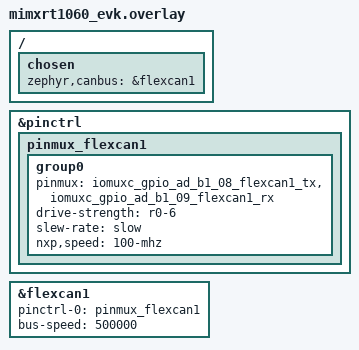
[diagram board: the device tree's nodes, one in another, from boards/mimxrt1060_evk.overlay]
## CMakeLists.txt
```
cmake_minimum_required(VERSION 3.20.0)

find_package(Zephyr REQUIRED HINTS $ENV{ZEPHYR_BASE})

project(zephyr_can_monitor VERSION 1.0.0)

target_sources(app PRIVATE
    src/main.c
    src/can_monitor.c
    src/can_tx.c
    src/logger.c
)

target_include_directories(app PRIVATE src)
```

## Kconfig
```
mainmenu "CAN Monitor"

source "Kconfig.zephyr"

rsource "Kconfig.appsymbols"
```

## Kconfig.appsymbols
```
# App-specific Kconfig symbols shared between the application and unit tests.
# Sourced from the root Kconfig and from each test's Kconfig.

menu "CAN Logger Configuration"

config CAN_LOGGER_BITRATE
	int "CAN bus bitrate (bps)"
	default 500000
	help
	  CAN bus bitrate in bits per second.
	  Common values: 125000, 250000, 500000, 1000000.

config CAN_TX1_PERIOD_MS
	int "TX message 1 period (ms)"
	default 100
	range 10 60000
	help
	  Transmit interval for TX message 1 in milliseconds.

config CAN_TX2_PERIOD_MS
	int "TX message 2 period (ms)"
	default 500
	range 10 60000
	help
	  Transmit interval for TX message 2 in milliseconds.

config CAN_TX3_PERIOD_MS
	int "TX message 3 period (ms)"
	default 1000
	range 10 60000
	help
	  Transmit interval for TX message 3 in milliseconds.

config CAN_TX1_ID
	hex "TX message 1 CAN ID (11-bit)"
	default 0x101
	range 0x001 0x7FF
	help
	  11-bit CAN ID used for the first periodic TX message.

config CAN_TX2_ID
	hex "TX message 2 CAN ID (11-bit)"
	default 0x102
	range 0x001 0x7FF
	help
	  11-bit CAN ID used for the second periodic TX message.

config CAN_TX3_ID
	hex "TX message 3 CAN ID (11-bit)"
	default 0x103
	range 0x001 0x7FF
	help
	  11-bit CAN ID used for the third periodic TX message.

config CAN_ID_START_ENABLED
	bool "Enable start logging RX ID"
	default n
	help
	  When enabled, logging does not begin until a CAN frame with
	  CAN_ID_START is received. When disabled, logging starts immediately.

config CAN_ID_START
	hex "RX CAN ID to start logging"
	depends on CAN_ID_START_ENABLED
	default 0x200
	range 0x001 0x7FF
	help
	  Receiving a frame with this ID transitions the logger from IDLE to
	  ACTIVE. Only meaningful when CAN_ID_START_ENABLED=y.

config CAN_ID_STOP_ENABLED
	bool "Enable stop logging RX ID"
	default n
	help
	  When enabled, a CAN frame with CAN_ID_STOP stops logging.
	  When disabled, logging continues indefinitely.

config CAN_ID_STOP
	hex "RX CAN ID to stop logging"
	depends on CAN_ID_STOP_ENABLED
	default 0x201
	range 0x001 0x7FF
	help
	  Receiving a frame with this ID transitions the logger from ACTIVE to
	  IDLE. Only meaningful when CAN_ID_STOP_ENABLED=y.

config CAN_ID_HELLO_ENABLED
	bool "Enable 'hello specialized' RX ID"
	default n
	help
	  When enabled, receiving a frame with CAN_ID_HELLO prints the string
	  "hello specialized" over UART regardless of the current logging state.

config CAN_ID_HELLO
	hex "RX CAN ID to print 'hello specialized'"
	depends on CAN_ID_HELLO_ENABLED
	default 0x202
	range 0x001 0x7FF
	help
	  Receiving a frame with this ID prints "hello specialized" to UART.

endmenu

config CAN_LOOPBACK_MODE
	bool "Start CAN controller in loopback mode"
	default n
	help
	  Use CAN_MODE_LOOPBACK instead of CAN_MODE_NORMAL.
	  Required for zephyr,can-loopback (native_sim testing).
```

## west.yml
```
manifest:
  version: "1.2"

  remotes:
    - name: zephyrproject-rtos
      url-base: https://github.com/zephyrproject-rtos

  defaults:
    remote: zephyrproject-rtos
    revision: v3.7.0

  projects:
    - name: zephyr
      path: deps/zephyr
      import: true

  self:
    path: .          # T2 topology
```

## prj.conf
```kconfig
# --- Kernel ---
CONFIG_MAIN_STACK_SIZE=2048
CONFIG_SYSTEM_WORKQUEUE_STACK_SIZE=1024

# --- CAN driver ---
CONFIG_CAN=y

# --- UART console ---
CONFIG_UART_CONSOLE=y
CONFIG_PRINTK=y

# --- Random number generator ---
CONFIG_ENTROPY_GENERATOR=y

# --- Application options ---
CONFIG_CAN_LOGGER_BITRATE=500000

CONFIG_CAN_TX1_PERIOD_MS=100
CONFIG_CAN_TX2_PERIOD_MS=500
CONFIG_CAN_TX3_PERIOD_MS=1000

CONFIG_CAN_TX1_ID=0x101
CONFIG_CAN_TX2_ID=0x102
CONFIG_CAN_TX3_ID=0x103

# Optional RX control IDs — disabled by default (Kconfig defaults: n).
# Enable via boards/<board>.conf or: west build -- -DCONFIG_CAN_ID_START_ENABLED=y ...
```

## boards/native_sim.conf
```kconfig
CONFIG_CAN_ID_START_ENABLED=n
CONFIG_CAN_ID_STOP_ENABLED=n
CONFIG_CAN_LOOPBACK_MODE=y
```

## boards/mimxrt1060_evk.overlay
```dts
/ {
	chosen {
		zephyr,canbus = &flexcan1;
	};
};

&pinctrl {
	pinmux_flexcan1: pinmux_flexcan1 {
		group0 {
			pinmux = <&iomuxc_gpio_ad_b1_08_flexcan1_tx>,
				 <&iomuxc_gpio_ad_b1_09_flexcan1_rx>;
			drive-strength = "r0-6";
			slew-rate = "slow";
			nxp,speed = "100-mhz";
		};
	};
};

&flexcan1 {
	status = "okay";
	pinctrl-0 = <&pinmux_flexcan1>;
	pinctrl-names = "default";
	bus-speed = <500000>;
};
```

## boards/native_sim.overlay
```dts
/ {
	chosen {
		zephyr,canbus = &can_loopback0;
	};
};

&can_loopback0 {
	status = "okay";
};
```

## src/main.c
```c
#include <zephyr/kernel.h>
#include <zephyr/drivers/can.h>
#include <zephyr/devicetree.h>

#include "can_monitor.h"
#include "can_tx.h"

int main(void)
{
	int err;

	/* ------------------------------------------------------------------
	 * 1. Get the CAN device from the device tree
	 * ------------------------------------------------------------------ */
	const struct device *can_dev = DEVICE_DT_GET(DT_CHOSEN(zephyr_canbus));

	if (!device_is_ready(can_dev)) {
		printk("CAN device not ready — halting\n");
		return -ENODEV;
	}

	/* ------------------------------------------------------------------
	 * 2. Configure CAN mode and start the controller
	 * ------------------------------------------------------------------ */
	can_mode_t mode = IS_ENABLED(CONFIG_CAN_LOOPBACK_MODE)
		? CAN_MODE_LOOPBACK : CAN_MODE_NORMAL;
	err = can_set_mode(can_dev, mode);
	if (err != 0) {
		printk("can_set_mode failed (%d)\n", err);
		return err;
	}

	err = can_start(can_dev);
	if (err != 0) {
		printk("can_start failed (%d)\n", err);
		return err;
	}

	printk("CAN logger started — bitrate %d bps\n",
	       CONFIG_CAN_LOGGER_BITRATE);

#if IS_ENABLED(CONFIG_CAN_ID_START_ENABLED)
	printk("  Waiting for start ID 0x%03X\n", CONFIG_CAN_ID_START);
#else
	printk("  Logging immediately\n");
#endif

	can_monitor_init(can_dev);

	can_tx_init(can_dev);

	return 0;
}
```

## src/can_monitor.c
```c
#include "can_monitor.h"
#include "logger.h"

#include <zephyr/kernel.h>
#include <zephyr/drivers/can.h>

static logging_state_t g_state;

static uint32_t g_hello_count;
static uint32_t g_log_count;

K_MSGQ_DEFINE(rx_msgq, sizeof(struct can_frame), 32, 4);

static const struct can_filter pass_all_filter = {
	.id   = 0U,
	.mask = 0U,
	.flags = 0U,
};


static inline logging_state_t initial_state(void)
{
	return IS_ENABLED(CONFIG_CAN_ID_START_ENABLED)
		? LOGGING_IDLE
		: LOGGING_ACTIVE;
}

void can_monitor_dispatch(const struct can_frame *frame)
{
#if IS_ENABLED(CONFIG_CAN_ID_HELLO_ENABLED)
	if (frame->id == CONFIG_CAN_ID_HELLO) {
		printk("hello world\n");
		g_hello_count++;
		return; /* Do not log this frame */
	}
#endif

#if IS_ENABLED(CONFIG_CAN_ID_START_ENABLED)
	if (frame->id == CONFIG_CAN_ID_START && g_state == LOGGING_IDLE) {
		g_state = LOGGING_ACTIVE;
		return;
	}
#endif

#if IS_ENABLED(CONFIG_CAN_ID_STOP_ENABLED)
	if (frame->id == CONFIG_CAN_ID_STOP && g_state == LOGGING_ACTIVE) {
		g_state = LOGGING_IDLE;
		return;
	}
#endif

	if (g_state == LOGGING_ACTIVE) {
		logger_print_frame(frame, k_uptime_get());
		g_log_count++;
	}
}

void can_monitor_init(const struct device *can_dev)
{
	g_state      = initial_state();
	g_hello_count = 0U;
	g_log_count   = 0U;

	int filter_id = can_add_rx_filter_msgq(can_dev, &rx_msgq,
					       &pass_all_filter);
	if (filter_id < 0) {
		printk("can_monitor: failed to add RX filter (%d)\n",
		       filter_id);
	}
}

void can_monitor_reset(void)
{
	g_state       = initial_state();
	g_hello_count = 0U;
	g_log_count   = 0U;
}

logging_state_t can_monitor_get_state(void)
{
	return g_state;
}

uint32_t can_monitor_get_hello_count(void)
{
	return g_hello_count;
}

uint32_t can_monitor_get_log_count(void)
{
	return g_log_count;
}

static void monitor_thread_entry(void *arg1, void *arg2, void *arg3)
{
	ARG_UNUSED(arg1);
	ARG_UNUSED(arg2);
	ARG_UNUSED(arg3);

	struct can_frame frame;

	while (1) {
		/* Block until a frame is available */
		k_msgq_get(&rx_msgq, &frame, K_FOREVER);
		can_monitor_dispatch(&frame);
	}
}

K_THREAD_DEFINE(monitor_tid,
		2048,
		monitor_thread_entry,
		NULL, NULL, NULL,
		5,                  /* priority (preemptible)        */
		0,                  /* options                       */
		0);                 /* start delay (ms) — 0 = now    */
```

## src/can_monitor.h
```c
#ifndef CAN_MONITOR_H
#define CAN_MONITOR_H

#include <zephyr/drivers/can.h>

typedef enum {
	LOGGING_IDLE,
	LOGGING_ACTIVE,
} logging_state_t;

void can_monitor_init(const struct device *can_dev);

logging_state_t can_monitor_get_state(void);

void can_monitor_reset(void);
void can_monitor_dispatch(const struct can_frame *frame);

uint32_t can_monitor_get_hello_count(void);
uint32_t can_monitor_get_log_count(void);

#endif
```

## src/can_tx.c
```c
#include "can_tx.h"

#include <zephyr/kernel.h>
#include <zephyr/drivers/can.h>
#include <zephyr/random/random.h>

static const struct device *g_can_dev;

#define TX_STACK_SIZE 1024

static struct k_thread tx_thread_data[3];

K_THREAD_STACK_ARRAY_DEFINE(tx_stacks, 3, TX_STACK_SIZE);

struct tx_cfg {
	uint32_t id;
	uint32_t period_ms;
};

static const struct tx_cfg tx_cfgs[3] = {
	{ CONFIG_CAN_TX1_ID, CONFIG_CAN_TX1_PERIOD_MS },
	{ CONFIG_CAN_TX2_ID, CONFIG_CAN_TX2_PERIOD_MS },
	{ CONFIG_CAN_TX3_ID, CONFIG_CAN_TX3_PERIOD_MS },
};

static void tx_send_random(uint32_t can_id, uint32_t period_ms)
{
	struct can_frame frame = {
		.id    = can_id,
		.dlc   = 8,
		.flags = 0,
	};

	sys_rand_get(frame.data, sizeof(frame.data));

	int err = can_send(g_can_dev, &frame, K_MSEC(10), NULL, NULL);

	if (err != 0) {
		printk("can_tx: send 0x%03X failed (%d)\n", can_id, err);
	}

	k_sleep(K_MSEC(period_ms));
}

static void tx_entry(void *p1, void *p2, void *p3)
{
	ARG_UNUSED(p2);
	ARG_UNUSED(p3);

	const struct tx_cfg *cfg = p1;

	while (1) {
		tx_send_random(cfg->id, cfg->period_ms);
	}
}

void can_tx_init(const struct device *can_dev)
{
	g_can_dev = can_dev;

	for (int i = 0; i < 3; i++) {
		k_thread_create(&tx_thread_data[i], tx_stacks[i],
				TX_STACK_SIZE,
				tx_entry, (void *)&tx_cfgs[i], NULL, NULL,
				7, 0, K_NO_WAIT);
		k_thread_name_set(&tx_thread_data[i], i == 0 ? "can_tx1"
							      : i == 1 ? "can_tx2"
								       : "can_tx3");
	}
}
```

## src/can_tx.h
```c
#ifndef CAN_TX_H
#define CAN_TX_H

#include <zephyr/drivers/can.h>

void can_tx_init(const struct device *can_dev);

#endif
```

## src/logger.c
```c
#include "logger.h"

#include <stdio.h>
#include <zephyr/kernel.h>

#define LOGGER_BUF_LEN 72

int logger_format_frame(char *buf, size_t buf_len,
			const struct can_frame *frame, int64_t ts_ms)
{
	int pos = 0;
	int ret;

	if (frame == NULL || buf == NULL || buf_len == 0) {
		if (buf != NULL && buf_len > 0) {
			buf[0] = '\0';
		}
		return 0;
	}

	/* Timestamp and header */
	ret = snprintf(buf + pos, buf_len - pos,
		       "[%lld] ID=0x%03X DLC=%d DATA=",
		       (long long)ts_ms, frame->id, frame->dlc);
	if (ret < 0 || (size_t)ret >= buf_len - pos) {
		return ret;
	}
	pos += ret;

	/* Data bytes */
	for (uint8_t i = 0; i < frame->dlc; i++) {
		const char *sep = (i == 0) ? "" : " ";

		ret = snprintf(buf + pos, buf_len - pos,
			       "%s%02X", sep, frame->data[i]);
		if (ret < 0 || (size_t)ret >= buf_len - pos) {
			break;
		}
		pos += ret;
	}

	return pos;
}

void logger_print_frame(const struct can_frame *frame, int64_t ts_ms)
{
	char buf[LOGGER_BUF_LEN];

	logger_format_frame(buf, sizeof(buf), frame, ts_ms);
	printk("%s\n", buf);
}
```

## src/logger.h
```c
#ifndef LOGGER_H
#define LOGGER_H

#include <stddef.h>
#include <stdint.h>
#include <zephyr/drivers/can.h>

int logger_format_frame(char *buf, size_t buf_len,
			const struct can_frame *frame, int64_t ts_ms);

void logger_print_frame(const struct can_frame *frame, int64_t ts_ms);

#endif
```
